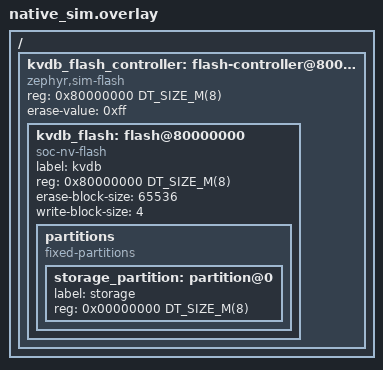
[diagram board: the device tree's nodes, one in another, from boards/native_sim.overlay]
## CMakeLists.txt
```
#-------------------------------------------------------------------------------
# kvdb diagnostics: a shell over the storage stack
#
# Copyright (c) 2026
# SPDX-License-Identifier: Apache-2.0

cmake_minimum_required(VERSION 3.20.0)
find_package(Zephyr REQUIRED HINTS $ENV{ZEPHYR_BASE})

project(app_diag LANGUAGES C)

target_sources(app PRIVATE src/main.c)

# `diag`: structure recognition, with the formats compiled in here.
target_sources_ifdef(CONFIG_APP_DIAG_STRUCT app PRIVATE
	src/diag_shell.c
	src/diag_decode.c
	src/diag_cbor.c
)
```

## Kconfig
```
# kvdb diagnostics app — Kconfig entry point.
#
# Copyright (c) 2026
# SPDX-License-Identifier: Apache-2.0

menu "Zephyr"
source "Kconfig.zephyr"
endmenu

module = APP_DIAG
module-str = APP_DIAG
source "subsys/logging/Kconfig.template.log_config"

config APP_DIAG_MOUNT_AT_BOOT
	bool "Mount blob_db at boot"
	help
	  Call blob_db_mount() from main() before the shell takes over, as
	  `blob_db mount` would.

	  Off by default because mounting is not read-only. A mount finishes
	  an interrupted compaction from the scratch seal, formats a partition
	  whose master sectors both read as erased, and, on the UBI backend,
	  attaches the volume. Each of those writes flash, and each can change
	  the state a diagnostic session was meant to look at. Off, the app
	  touches the storage partition only through the commands typed at it:
	  "flash" reads raw bytes, "blob_db" answers "not mounted" until
	  `blob_db mount` or `blob_db format yes` is run.

config APP_DIAG_STRUCT
	bool "diag: recognise and decode structures"
	default y
	depends on SHELL && BLOB_DB_INSPECT
	help
	  Add a `diag` shell group that names what each live object is: the
	  root registry, kvdb and blobfs metas, the persondb superblock,
	  kvhash directories and buckets, logring roots and entries. `scan`
	  classifies every object and counts them by type, `roots` walks the
	  root registry one level down, `show` decodes one object.

	  The formats, the current ones and those earlier builds wrote, are
	  compiled into app_diag (src/diag_decode.c); the libraries carry none
	  of this. Read-only: only blob_db_size(), blob_db_read() and the
	  inspect API are called.

config APP_DIAG_BUF_SIZE
	int "Bytes of one object diag reads"
	default BLOB_DB_MAX_PAYLOAD_LEN
	range 64 65536
	depends on APP_DIAG_STRUCT
	help
	  An object is read into one static buffer of this size to be
	  classified and decoded. A larger object is judged by its first
	  bytes only. Every structure head and kvhash bucket fits in one
	  payload, so the default covers all of them.

config APP_DIAG_HINTS_MAX
	int "References diag tracks from the root registry"
	default 32
	range 4 1024
	depends on APP_DIAG_STRUCT
	help
	  `diag scan` labels the registry's roots, and what each root points
	  at, with where they are referenced from, and lists those that name
	  no object. This many fit; 24 bytes each.
```

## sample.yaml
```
sample:
  description: kvdb diagnostics shell (existing commands, no mount by default)
  name: kvdb-diag
common:
  tags: [storage, shell]
  harness: console
tests:
  # The default build: boots to the shell and leaves the store unmounted.
  app.diag:
    platform_allow:
      - native_sim
    integration_platforms:
      - native_sim
    harness_config:
      type: multi_line
      ordered: true
      regex:
        - "kvdb diag: UBI backend, storage partition 8192 KiB"
        - "kvdb diag: not mounted"

  # Mount at boot opted in: a blank image is formatted and mounted.
  app.diag.mount:
    platform_allow:
      - native_sim
    extra_configs:
      - CONFIG_APP_DIAG_MOUNT_AT_BOOT=y
    harness_config:
      type: one_line
      regex:
        - "kvdb diag: mounted"

  # The lifecycle commands, typed at the shell: format refused without `yes`,
  # mount, remount, unmount, format. Commands and replies: test_shell.yml.
  app.diag.admin:
    platform_allow:
      - native_sim
    harness: shell
    harness_config:
      shell_commands_file: test_shell.yml

  # `kernel reboot cold` restarts unmounted, and the store formatted before it
  # mounts again without being formatted. A pytest test rather than a
  # test_shell.yml step: the restarted shell's first prompt needs waiting for.
  app.diag.reboot:
    platform_allow:
      - native_sim
    harness: pytest
    harness_config:
      pytest_root:
        - "pytest/test_reboot.py"

  # A dump made on the host is imported line by line into a fresh store and
  # exported again: every object comes back at its own id, with next_id.
  app.diag.export:
    platform_allow:
      - native_sim
    harness: pytest
    harness_config:
      pytest_root:
        - "pytest/test_export.py"

  # The same with large payloads: one object is segmented.
  app.diag.export.large:
    platform_allow:
      - native_sim
    extra_configs:
      - CONFIG_BLOB_DB_LARGE_PAYLOADS=y
    harness: pytest
    harness_config:
      pytest_root:
        - "pytest/test_export.py"

  # `diag`: a store imported from pytest/diag_fixtures.py, one object in every
  # structure format diag knows, current and past, is scanned, walked from
  # the registry and decoded object by object. One device for the module:
  # the store is imported once.
  app.diag.structs:
    platform_allow:
      - native_sim
    harness: pytest
    harness_config:
      pytest_dut_scope: module
      pytest_root:
        - "pytest/test_structs.py"
```

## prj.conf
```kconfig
# kvdb diagnostics app: the storage stack plus the shell commands that already
# exist for it. The app adds no commands of its own.
#
# Copyright (c) 2026
# SPDX-License-Identifier: Apache-2.0

# A diagnostics build compiles in the stack's debug messages, which a product
# build leaves out: mount's master classification, recovery decisions, UBI
# attach. They are on from boot; `log enable <level> <module>` turns a module
# down at run time.
#
# Immediate mode: each message is printed by the call that logs it, so it
# lands before the shell's reply to the command that caused it, and a burst of
# debug output is not dropped from a full buffer.
CONFIG_LOG=y
CONFIG_LOG_MODE_IMMEDIATE=y
CONFIG_LOG_RUNTIME_FILTERING=y
CONFIG_LOG_RUNTIME_DEFAULT_LEVEL=4
CONFIG_APP_DIAG_LOG_LEVEL_DBG=y
CONFIG_BLOB_DB_LOG_LEVEL_DBG=y
CONFIG_UBI_LOG_LEVEL_DBG=y

# The store, on the default backend (UBI with the built-in key). An image is
# readable only by a build that agrees with the one that wrote it on the
# backend, the UBI key and every option that changes the on-flash format
# (BLOB_DB_LARGE_PAYLOADS, BLOB_DB_MAX_PAYLOAD_LEN); match those to the
# firmware whose store is being inspected.
CONFIG_BLOB_DB=y

# Nothing in the build may write the partition on its own. The store is
# mounted by `blob_db mount`, or at boot only with
# CONFIG_APP_DIAG_MOUNT_AT_BOOT (default n); a corrupt one
# is never reformatted; no work item runs maintenance in the background; and
# blobfs is left out, since its file-system registration is another way to a
# mount.
CONFIG_BLOB_DB_AUTOFORMAT_ON_CORRUPT=n
CONFIG_BLOB_DB_MAINT_WORK=n

# The existing command groups.
CONFIG_SHELL=y
CONFIG_SHELL_PROMPT_UART="kvdb:~$ "
# blob_db info|stats|buckets|bucket|id|dump|maintain
CONFIG_BLOB_DB_SHELL=y
# blob_db iostats
CONFIG_BLOB_DB_IOSTATS=y
# blob_db mount|unmount|format yes
CONFIG_BLOB_DB_SHELL_ADMIN=y
# flash read|write|erase|... on the raw device
CONFIG_FLASH_SHELL=y
# kernel threads|stacks|uptime, device list
CONFIG_KERNEL_SHELL=y
CONFIG_DEVICE_SHELL=y
# kernel reboot cold|warm. Not an unmount: the store sees what it would see
# after a power cut between operations. On native_sim the process re-runs
# itself with the same arguments, so --kvdb=<file> and its content carry over.
CONFIG_REBOOT=y

# Export reads each object 32 bytes at a time, and without an index every
# blob_db_read() walks the object's whole bucket, one 12-byte read per slot:
# on a 13k-object store that is ~800 MB read to export 4.6 MB. With the slot
# index the first lookup of an object walks once and the rest go straight to
# its slot. It is a cache of hints (CLOCK keeps the ids in use; only the
# object being exported needs to stay), every hit is checked against flash,
# and nothing about it is written: it changes no answer and no byte on the
# store. Walks and known-offset reads fetch 512 bytes at a time instead of
# one slot header or one field per flash command. RAM: 3 KB of index plus
# 1.5 KB of bucket cursors.
CONFIG_BLOB_DB_SLOT_INDEX=y
CONFIG_BLOB_DB_SLOT_INDEX_CLOCK=y
CONFIG_BLOB_DB_SLOT_INDEX_ENTRIES=256
CONFIG_BLOB_DB_WALK_CHUNK=512
CONFIG_BLOB_DB_READ_WINDOW=512

# `blob_db maintain` with a budget runs UBI relocations, and their AES-CMAC,
# on the shell thread.
CONFIG_SHELL_STACK_SIZE=16384

# A mount at boot runs on main: UBI attach plus blob_db's master and bucket
# scan, the same work app_perf_blob_db gives 32 KB.
CONFIG_MAIN_STACK_SIZE=32768
```

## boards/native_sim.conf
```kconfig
# The shell on the terminal native_sim was started from, not on a pty, so the
# host build is used like any command-line tool; commands can also be piped in.
CONFIG_UART_NATIVE_PTY_0_ON_STDINOUT=y

# Program-over-programmed (1->0 only) is legal on the NOR this geometry
# models; the flash simulator refuses it unless told otherwise.
CONFIG_FLASH_SIMULATOR_DOUBLE_WRITES=y

# The overlay gives the store's flash the DK's 64 KB erase blocks; blob_db
# refuses to mount a sector larger than its sector buffer.
CONFIG_BLOB_DB_SECTOR_BUF_SIZE=65536

# zephyr-ubi's heap: 8 B per erase block (128 of 64 KB, so 1 KB) plus a
# handle and scratch buffer at attach and a second pair during a format.
CONFIG_BLOB_DB_UBI_HEAP_SIZE=6144

# The native log backend already prints to the terminal the shell is on; the
# shell's own log backend would print every line a second time.
CONFIG_SHELL_LOG_BACKEND=n

# `kernel reboot` re-runs the executable with the same arguments, so the
# image named by --kvdb survives it. Without this it only exits.
CONFIG_NATIVE_SIM_REBOOT=y

# `blob_db import` stages each object whole, so the host build restores any
# object up to BLOB_DB_MAX_OBJECT_LEN's default with one blob_db_update(), as
# the original was written.
CONFIG_BLOB_DB_SHELL_IMPORT_BUF_SIZE=131072

# The shell polls its input every 10 ms by default; a host feeding
# `blob_db import` one line at a time waits that long per line.
CONFIG_SHELL_BACKEND_SERIAL_RX_POLL_PERIOD=1
```

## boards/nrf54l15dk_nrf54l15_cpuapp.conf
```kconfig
# blob_db stages a whole erase block in .bss; the MX25R6435F's is 64 KB.
CONFIG_BLOB_DB_SECTOR_BUF_SIZE=65536

# zephyr-ubi's heap: 8 B per erase block (128 of 64 KB, so 1 KB) plus a handle
# and scratch buffer at attach and a second pair during a format.
CONFIG_BLOB_DB_UBI_HEAP_SIZE=6144

# RAM: the nRF54L15 has 256 KB. AES T-tables (zephyr-ubi's header CMAC) in
# flash instead of RAM: 8 KB.
CONFIG_MBEDTLS_AES_ROM_TABLES=y
```

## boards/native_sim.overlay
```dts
/*
 * Copyright (c) 2026
 * SPDX-License-Identifier: Apache-2.0
 *
 * native_sim: the store gets a simulated flash device of its own, shaped like
 * the nRF5340-DK's on-board MX25R6435F partition (8 MB, 64 KB erase blocks,
 * 4 B write alignment, erased = 0xff). The partition starts at offset 0 and
 * fills the device, so the device's backing file IS a partition image:
 *
 *   ./zephyr.exe --kvdb=storage.bin
 *
 * opens a raw dump of the DK's storage partition as it is, and a file the
 * host build leaves behind can be programmed back unchanged.
 *
 * The board's own flash0 keeps its MCUboot and image partitions; only its
 * small storage partition is removed so that storage_partition, the node
 * label blob_db binds to, names this one.
 */

/delete-node/ &storage_partition;

/ {
	kvdb_flash_controller: flash-controller@80000000 {
		compatible = "zephyr,sim-flash";
		reg = <0x80000000 DT_SIZE_M(8)>;
		ranges;
		#address-cells = <1>;
		#size-cells = <1>;
		erase-value = <0xff>;

		kvdb_flash: flash@80000000 {
			compatible = "soc-nv-flash";
			/* Names the --kvdb, --kvdb_erase, --kvdb_rm and --kvdb_in_ram
			 * command-line options of the flash simulator.
			 */
			label = "kvdb";
			reg = <0x80000000 DT_SIZE_M(8)>;
			erase-block-size = <65536>;
			write-block-size = <4>;

			partitions {
				compatible = "fixed-partitions";
				#address-cells = <1>;
				#size-cells = <1>;

				storage_partition: partition@0 {
					label = "storage";
					reg = <0x00000000 DT_SIZE_M(8)>;
				};
			};
		};
	};
};
```

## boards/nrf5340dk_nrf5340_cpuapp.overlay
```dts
/*
 * The store on the on-board MX25R64 QSPI NOR: its first 8 MB, 64 KB sectors,
 * as in app_perf_blob_db. The native_sim build of this app models the same
 * partition, so a raw dump of this range opens there unchanged.
 */

/delete-node/ &storage_partition;

&mx25r64 {
	partitions {
		compatible = "fixed-partitions";
		#address-cells = <1>;
		#size-cells = <1>;

		storage_partition: partition@0 {
			label = "storage";
			reg = <0x00000000 0x00800000>;
		};
	};
};
```

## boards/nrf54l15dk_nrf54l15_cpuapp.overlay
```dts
/*
 * The store on the nRF54L15-DK's MX25R64: the same chip as the nRF5340-DK's,
 * but on SPI00 (jedec,spi-nor, single line, 8 MHz) rather than QSPI. The whole
 * chip, 64 KB sectors, as app_cbor_persondb and nrf_ble_scanner_with_db lay it
 * out on this board.
 *
 * The SoC's internal storage_partition (RRAM) is removed so that the label
 * "storage" names the external part only.
 *
 * spi-nor's write block is 1 B (QSPI: 4 B), so an image written here does not
 * open on the nRF5340-DK build or on native_sim's default, and the other way
 * round.
 */

/delete-node/ &storage_partition;

&mx25r64 {
	partitions {
		compatible = "fixed-partitions";
		#address-cells = <1>;
		#size-cells = <1>;

		storage_partition: partition@0 {
			label = "storage";
			reg = <0x00000000 0x00800000>;
		};
	};
};
```

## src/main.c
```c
/*
 * Copyright (c) 2026
 * SPDX-License-Identifier: Apache-2.0
 *
 * kvdb diagnostics: an application that does nothing but expose the shell.
 *
 * The commands are the ones the libraries and Zephyr register (blob_db,
 * flash, kernel, device), plus the app's own `diag` (diag_shell.c), which
 * recognises the structures in the store. This file says what was built, and
 * mounts the store only when CONFIG_APP_DIAG_MOUNT_AT_BOOT asks for it: by
 * default nothing writes the storage partition until a command typed at the
 * shell does (`blob_db mount`, `blob_db format yes`, `flash write`).
 */

#include <zephyr/kernel.h>
#include <zephyr/logging/log.h>
#include <zephyr/storage/flash_map.h>

#include <app/lib/blob_db.h>

LOG_MODULE_REGISTER(app_diag, CONFIG_APP_DIAG_LOG_LEVEL);

int main(void)
{
	LOG_INF("kvdb diag: %s backend, storage partition %u KiB on %s",
		IS_ENABLED(CONFIG_BLOB_DB_BACKEND_UBI) ? "UBI" : "flash_area",
		(unsigned int)(PARTITION_SIZE(storage_partition) / 1024U),
		PARTITION_DEVICE(storage_partition)->name);

	if (!IS_ENABLED(CONFIG_APP_DIAG_MOUNT_AT_BOOT)) {
		LOG_INF("kvdb diag: not mounted; `blob_db mount` mounts");
		return 0;
	}

	int rc = blob_db_mount();

	if (rc != 0) {
		LOG_ERR("kvdb diag: mount failed: %d", rc);
		return 0;
	}
	LOG_INF("kvdb diag: mounted");
	return 0;
}
```

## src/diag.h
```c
/*
 * Copyright (c) 2026
 * SPDX-License-Identifier: Apache-2.0
 *
 * app_diag structure recognition: what a blob is, judged from its bytes.
 *
 * The formats are the ones the libraries write, copied here on purpose
 * together with the layouts earlier builds wrote, so that an image from an
 * older firmware is still named and decoded. Nothing in this directory is
 * used by the libraries, and nothing here calls into a container: the only
 * dependency is the public blob_db API (plus the inspect API to enumerate).
 *
 * Every judgement is a guess from the bytes. A magic and a length that agree
 * with it make a strong guess; a layout without a magic (a kvhash bucket, a
 * logring entry) is a weak one, reported as "shape". A file body or a spilled
 * value can hold any bytes, including another structure's magic.
 */

#ifndef APP_DIAG_DIAG_H_
#define APP_DIAG_DIAG_H_

#include <stdbool.h>
#include <stddef.h>
#include <stdint.h>

struct shell;

/** What a blob was recognised as. The order is the order of the summary. */
enum diag_type {
	DIAG_T_RREG,          /**< root registry (id 1)                       */
	DIAG_T_KVDB_META,     /**< kvdb instance meta                         */
	DIAG_T_BLOBFS_META,   /**< blobfs file-system meta                    */
	DIAG_T_PADB_SB,       /**< app_cbor_persondb superblock (CBOR)        */
	DIAG_T_KVHASH_DIR,    /**< kvhash directory (map root or sub-map)     */
	DIAG_T_CLOG_ROOT,     /**< logring: root i-node or whole ring         */
	DIAG_T_KVHASH_BUCKET, /**< kvhash bucket (shape only)                 */
	DIAG_T_CLOG_ENTRY,    /**< logring chain entry (shape only)           */
	DIAG_T_CBOR,          /**< one well-formed CBOR item (shape only)     */
	DIAG_T_EMPTY,         /**< zero-length payload                        */
	DIAG_T_UNKNOWN,       /**< none of the above                          */
	DIAG_T_COUNT,
};

/** Most variants any one type has; see diag_type_info(). */
#define DIAG_VARIANTS_MAX 4

/** The verdict on one blob. */
struct diag_class {
	enum diag_type type;
	uint8_t variant;    /**< index into the type's variant names     */
	bool    shape;      /**< no magic: recognised by layout alone    */
	bool    suspect;    /**< magic matches, the rest does not quite  */
	const char *note;   /**< static text: why suspect, or a state    */
};

/** Static description of a type, for summaries and `diag formats`. */
struct diag_type_info {
	const char *name;                             /**< short tag    */
	const char *what;                             /**< one line     */
	const char *variant[DIAG_VARIANTS_MAX];       /**< NULL-ended   */
};

const struct diag_type_info *diag_type_info(enum diag_type t);

/** Look a type up by its short tag (for `diag show <id> <type>`). */
int diag_type_by_name(const char *name, enum diag_type *out);

/**
 * @brief Classify a blob.
 *
 * @param id    the blob's id (a logring entry links forward, to a larger id)
 * @param buf   the payload, or its first @p n bytes
 * @param n     bytes in @p buf
 * @param size  the blob's full length; > @p n when only a prefix was read,
 *              in which case the shape-only checks, which need the whole
 *              payload, are skipped
 */
void diag_classify(uint64_t id, const uint8_t *buf, size_t n, size_t size,
		   struct diag_class *out);

/**
 * @brief Classify a blob as type @p t whatever its bytes say, for decoding
 *        a blob without a magic (a kvhash bucket, a logring entry) or one
 *        the classifier got wrong.
 *
 * @retval 0         @p out filled; marked suspect if @p t is not what
 *                   diag_classify() would have said
 * @retval -EMSGSIZE too short to hold a @p t header
 */
int diag_force(uint64_t id, enum diag_type t, const uint8_t *buf, size_t n,
	       size_t size, struct diag_class *out);

/**
 * @brief One line: the id, type, variant and the fields that identify the
 *        instance, after @p prefix (indentation, a label) and before
 *        @p suffix (who references it); either may be "".
 */
void diag_summary(const struct shell *sh, const char *prefix, uint64_t id,
		  const struct diag_class *c, const uint8_t *buf, size_t n,
		  size_t size, const char *suffix);

/**
 * @brief Decode a blob in full, as type @p c->type, variant @p c->variant.
 *
 * Every id the structure references is printed, so that the next
 * `diag show` can follow it.
 */
void diag_decode(const struct shell *sh, uint64_t id,
		 const struct diag_class *c, const uint8_t *buf, size_t n,
		 size_t size);

/** One id a structure's head points at. */
struct diag_ref {
	uint64_t id;
	const char *label;  /**< static: what the field is ("struct_root") */
};

/**
 * @brief The ids a structure head references, as far as one blob tells:
 *        a kvdb meta's map, a blobfs meta's root directory, a persondb
 *        superblock's tables, a logring root's head. A kvhash directory's
 *        children are not listed here (they can be hundreds); `diag show`
 *        prints them.
 *
 * @return number of refs written to @p out (at most @p max)
 */
int diag_refs(const struct diag_class *c, const uint8_t *buf, size_t n,
	      struct diag_ref *out, int max);

/* ---- root registry keys --------------------------------------------- */

/** Name of a registry key's FourCC when it is one this tool knows, or NULL. */
const char *diag_rreg_key_name(uint64_t key);

/**
 * @brief Walk a root registry image.
 * @retval 0       walked
 * @retval -EINVAL not a registry this tool reads
 */
int diag_rreg_foreach(const uint8_t *buf, size_t n,
		      void (*cb)(uint64_t key, uint64_t root, void *user),
		      void *user);

/* ---- CBOR (diag_cbor.c) ---------------------------------------------- */

/** Length of the one well-formed item at @p p, or a negative errno. */
int diag_cbor_item_len(const uint8_t *p, size_t n, size_t *len);

/**
 * @brief Format the item at @p p in CBOR diagnostic notation, compactly
 *        (`{1: 2, 2: [5, 6], 3: "ab"}`), into @p out. Long output ends in
 *        "...".
 * @return bytes of input consumed, or a negative errno
 */
int diag_cbor_format(const uint8_t *p, size_t n, char *out, size_t out_sz);

/** Minimal reader for decoding known CBOR layouts field by field. */
struct diag_cbor {
	const uint8_t *p;
	const uint8_t *end;
	bool err;
};

/** Major type of the next item (0..7), or -1 at the end or on error. */
int diag_cbor_peek(const struct diag_cbor *c);
/** Unsigned integer (major 0). */
bool diag_cbor_uint(struct diag_cbor *c, uint64_t *v);
/** Definite-length array (major 4) or map (major 5) header. */
bool diag_cbor_array(struct diag_cbor *c, uint64_t *n);
bool diag_cbor_map(struct diag_cbor *c, uint64_t *n);
/** Skip one whole item. */
bool diag_cbor_skip(struct diag_cbor *c);

#endif /* APP_DIAG_DIAG_H_ */
```

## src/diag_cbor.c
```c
/*
 * Copyright (c) 2026
 * SPDX-License-Identifier: Apache-2.0
 *
 * A small CBOR (RFC 8949) reader for app_diag: check that bytes are one
 * well-formed item, print it in diagnostic notation, and pick known layouts
 * apart field by field. It knows nothing of any schema, so it prints a record
 * a newer firmware wrote as faithfully as one this build could write.
 *
 * zcbor is not used: the decoders it generates take one schema each, and the
 * point here is to show bytes whose schema may not be the one compiled in.
 */

#include <errno.h>
#include <stdarg.h>
#include <string.h>

#include <zephyr/sys/printk.h>
#include <zephyr/sys/util.h>

#include "diag.h"

#define CBOR_DEPTH_MAX 16
#define CBOR_BREAK     0xff
#define CBOR_AI_INDEF  31

/* Read an item head: major type, argument, and whether the length is
 * indefinite. Advances *pp. */
static int head(const uint8_t **pp, const uint8_t *end, uint8_t *major,
		uint64_t *arg, bool *indef)
{
	const uint8_t *p = *pp;

	if (p >= end) {
		return -ENODATA;
	}
	const uint8_t ib = *p++;
	const uint8_t ai = ib & 0x1f;

	*major = ib >> 5;
	*indef = false;
	if (ai < 24) {
		*arg = ai;
	} else if (ai <= 27) {
		const size_t w = 1u << (ai - 24);

		if ((size_t)(end - p) < w) {
			return -ENODATA;
		}
		*arg = 0;
		for (size_t i = 0; i < w; i++) {
			*arg = (*arg << 8) | *p++;
		}
	} else if (ai == CBOR_AI_INDEF &&
		   (*major == 2 || *major == 3 || *major == 4 || *major == 5)) {
		*indef = true;
		*arg = 0;
	} else {
		return -EILSEQ;   /* reserved, or a stray break */
	}
	*pp = p;
	return 0;
}

static int skip(const uint8_t **pp, const uint8_t *end, int depth)
{
	uint8_t major;
	uint64_t arg;
	bool indef;

	if (depth > CBOR_DEPTH_MAX) {
		return -ELOOP;
	}
	int rc = head(pp, end, &major, &arg, &indef);

	if (rc < 0) {
		return rc;
	}
	switch (major) {
	case 0: case 1: case 7:
		return 0;
	case 2: case 3:
		if (indef) {
			/* Chunks of the same major type, then a break. */
			while (*pp < end && **pp != CBOR_BREAK) {
				if ((**pp >> 5) != major) {
					return -EILSEQ;
				}
				rc = skip(pp, end, depth + 1);
				if (rc < 0) {
					return rc;
				}
			}
			if (*pp >= end) {
				return -ENODATA;
			}
			(*pp)++;
			return 0;
		}
		if (arg > (uint64_t)(end - *pp)) {
			return -ENODATA;
		}
		*pp += arg;
		return 0;
	case 6:
		return skip(pp, end, depth + 1);
	default: { /* 4: array, 5: map */
		const uint64_t per = (major == 5) ? 2 : 1;

		if (indef) {
			uint64_t items = 0;

			while (*pp < end && **pp != CBOR_BREAK) {
				rc = skip(pp, end, depth + 1);
				if (rc < 0) {
					return rc;
				}
				items++;
			}
			if (*pp >= end || items % per) {
				return *pp >= end ? -ENODATA : -EILSEQ;
			}
			(*pp)++;
			return 0;
		}
		/* Every item takes at least one byte: a count past the end
		 * is malformed, and bounding it here bounds the loop. */
		if (arg > (uint64_t)(end - *pp)) {
			return -ENODATA;
		}
		for (uint64_t i = 0; i < arg * per; i++) {
			rc = skip(pp, end, depth + 1);
			if (rc < 0) {
				return rc;
			}
		}
		return 0;
	}
	}
}

int diag_cbor_item_len(const uint8_t *p, size_t n, size_t *len)
{
	const uint8_t *q = p;
	int rc = skip(&q, p + n, 0);

	if (rc < 0) {
		return rc;
	}
	*len = (size_t)(q - p);
	return 0;
}

/* ---- diagnostic notation --------------------------------------------- */

struct fmt {
	char *buf;
	size_t sz;
	size_t len;
	bool full;
};

static __printf_like(2, 3) void put(struct fmt *f, const char *s, ...)
{
	if (f->full) {
		return;
	}
	va_list ap;

	va_start(ap, s);
	const int n = vsnprintk(f->buf + f->len, f->sz - f->len, s, ap);

	va_end(ap);
	/* Four bytes are always kept free for the "..." that marks a
	 * truncated line. */
	if (n < 0 || f->len + (size_t)n + 4 > f->sz) {
		f->full = true;
		strcpy(f->buf + f->sz - 4, "...");
		f->len = f->sz - 1;
		return;
	}
	f->len += (size_t)n;
}

#define FMT_BYTES_MAX 16

static int format(const uint8_t **pp, const uint8_t *end, struct fmt *f,
		  int depth)
{
	uint8_t major;
	uint64_t arg;
	bool indef;

	if (depth > CBOR_DEPTH_MAX) {
		return -ELOOP;
	}
	const uint8_t ib = (*pp < end) ? **pp : 0;
	int rc = head(pp, end, &major, &arg, &indef);

	if (rc < 0) {
		return rc;
	}
	switch (major) {
	case 0:
		put(f, "%llu", (unsigned long long)arg);
		return 0;
	case 1:
		if (arg == UINT64_MAX) {
			put(f, "-18446744073709551616");
		} else {
			put(f, "-%llu", (unsigned long long)arg + 1);
		}
		return 0;
	case 2: case 3:
		if (indef) {
			/* Shown as the chunks it was sent in, RFC 8949 §8. */
			put(f, "(_ ");
			for (int i = 0; *pp < end && **pp != CBOR_BREAK; i++) {
				put(f, i ? ", " : "");
				rc = format(pp, end, f, depth + 1);
				if (rc < 0) {
					return rc;
				}
			}
			if (*pp >= end) {
				return -ENODATA;
			}
			(*pp)++;
			put(f, ")");
			return 0;
		}
		if (arg > (uint64_t)(end - *pp)) {
			return -ENODATA;
		}
		if (major == 2) {
			put(f, "h'");
			for (uint64_t i = 0; i < MIN(arg, FMT_BYTES_MAX); i++) {
				put(f, "%02x", (*pp)[i]);
			}
			put(f, arg > FMT_BYTES_MAX ? "..'" : "'");
		} else {
			put(f, "\"");
			for (uint64_t i = 0; i < arg; i++) {
				const char c = (char)(*pp)[i];

				put(f, "%c", (c >= 0x20 && c < 0x7f && c != '"') ?
				    c : '.');
			}
			put(f, "\"");
		}
		*pp += arg;
		return 0;
	case 6:
		put(f, "%llu(", (unsigned long long)arg);
		rc = format(pp, end, f, depth + 1);
		put(f, ")");
		return rc;
	case 7:
		switch (arg) {
		case 20: put(f, "false"); break;
		case 21: put(f, "true"); break;
		case 22: put(f, "null"); break;
		case 23: put(f, "undefined"); break;
		default:
			/* Floats are shown by their bits: printk has no %f. */
			if (ib >= 0xf9 && ib <= 0xfb) {
				put(f, "float(0x%llx)", (unsigned long long)arg);
			} else {
				put(f, "simple(%llu)", (unsigned long long)arg);
			}
			break;
		}
		return 0;
	default: { /* 4: array, 5: map */
		const bool map = (major == 5);

		put(f, map ? "{" : "[");
		put(f, indef ? "_ " : "");
		if (!indef && arg > (uint64_t)(end - *pp)) {
			return -ENODATA;
		}
		for (uint64_t i = 0;; i++) {
			if (indef) {
				if (*pp >= end) {
					return -ENODATA;
				}
				if (**pp == CBOR_BREAK) {
					(*pp)++;
					break;
				}
			} else if (i == arg) {
				break;
			}
			put(f, i ? ", " : "");
			rc = format(pp, end, f, depth + 1);
			if (rc < 0) {
				return rc;
			}
			if (map) {
				put(f, ": ");
				rc = format(pp, end, f, depth + 1);
				if (rc < 0) {
					return rc;
				}
			}
		}
		put(f, map ? "}" : "]");
		return 0;
	}
	}
}

int diag_cbor_format(const uint8_t *p, size_t n, char *out, size_t out_sz)
{
	struct fmt f = { .buf = out, .sz = out_sz };
	const uint8_t *q = p;

	if (out_sz < 8) {
		return -ENOMEM;
	}
	out[0] = '\0';
	int rc = format(&q, p + n, &f, 0);

	return rc < 0 ? rc : (int)(q - p);
}

/* ---- field reader ---------------------------------------------------- */

int diag_cbor_peek(const struct diag_cbor *c)
{
	return (c->err || c->p >= c->end) ? -1 : (*c->p >> 5);
}

static bool expect(struct diag_cbor *c, uint8_t want, uint64_t *v)
{
	uint8_t major;
	bool indef;

	if (c->err || head(&c->p, c->end, &major, v, &indef) < 0 ||
	    major != want || indef) {
		c->err = true;
		return false;
	}
	return true;
}

bool diag_cbor_uint(struct diag_cbor *c, uint64_t *v)
{
	return expect(c, 0, v);
}

bool diag_cbor_array(struct diag_cbor *c, uint64_t *n)
{
	return expect(c, 4, n);
}

bool diag_cbor_map(struct diag_cbor *c, uint64_t *n)
{
	return expect(c, 5, n);
}

bool diag_cbor_skip(struct diag_cbor *c)
{
	if (c->err || skip(&c->p, c->end, 0) < 0) {
		c->err = true;
		return false;
	}
	return true;
}
```

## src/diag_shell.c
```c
/*
 * Copyright (c) 2026
 * SPDX-License-Identifier: Apache-2.0
 *
 * `diag`: name and decode the structures in a mounted store.
 *
 *   diag scan [-a]          every live object, classified; a census by type
 *   diag roots              the root registry, each root, what it points at
 *   diag show <id> [type]   one object decoded in full
 *   diag formats            the formats and past variants this build knows
 *
 * Read-only: only blob_db_size(), blob_db_read() and the inspect API are
 * called. The formats are in diag_decode.c; nothing here calls a container.
 */

#include <errno.h>
#include <stdlib.h>
#include <string.h>

#include <zephyr/shell/shell.h>
#include <zephyr/sys/printk.h>
#include <zephyr/sys/util.h>

#include <app/lib/blob_db.h>
#include <app/lib/blob_db_inspect.h>

#include "diag.h"

/* Ids gathered from a bucket per pass of its sector, as export does. */
#define SCAN_IDS  32
/* References followed per root by `roots` and the scan's labels. */
#define REFS_MAX  8

/* One object at a time: the shell thread is the only user. */
static uint8_t __aligned(4) g_buf[CONFIG_APP_DIAG_BUF_SIZE];

/* What points at an id, from the registry down one level: the labels the
 * scan prints, and the roots it checks are bound. */
struct hint {
	uint64_t id;
	uint64_t key;       /* registry key, for a root                    */
	uint64_t parent;    /* the root it hangs off; 0 for a root          */
	const char *label;  /* field in the parent                          */
	bool seen;
};

static struct hint g_hint[CONFIG_APP_DIAG_HINTS_MAX];
static int g_n_hint;
static bool g_hint_full;

static int parse_u64(const struct shell *sh, const char *s, uint64_t *out)
{
	char *end;

	errno = 0;
	*out = strtoull(s, &end, 0);
	if (errno || end == s || *end != '\0') {
		shell_error(sh, "not a number: %s", s);
		return -EINVAL;
	}
	return 0;
}

static int need_mount(const struct shell *sh, struct blob_db_inspect_info *in)
{
	int rc = blob_db_inspect_info_get(in);

	if (rc == -ENODEV) {
		shell_error(sh, "blob_db not mounted");
	} else if (rc < 0) {
		shell_error(sh, "info: %d", rc);
	}
	return rc;
}

/* Read an object, or its first sizeof(g_buf) bytes, into g_buf. */
static int read_obj(uint64_t id, size_t *size, size_t *n)
{
	int rc = blob_db_size(id, size);

	if (rc < 0) {
		return rc;
	}
	const size_t want = MIN(*size, sizeof(g_buf));
	size_t off = 0;

	while (off < want) {
		size_t got;

		rc = blob_db_read(id, off, g_buf + off, want - off, &got);
		if (rc < 0) {
			return rc;
		}
		if (got == 0) {
			return -EIO;   /* shrank since its size was taken */
		}
		off += got;
	}
	*n = want;
	return 0;
}

/* ---- hints ----------------------------------------------------------- */

static void hint_add(uint64_t id, uint64_t key, uint64_t parent,
		     const char *label)
{
	if (g_n_hint == ARRAY_SIZE(g_hint)) {
		g_hint_full = true;
		return;
	}
	g_hint[g_n_hint++] = (struct hint){
		.id = id, .key = key, .parent = parent, .label = label,
	};
}

static void hint_root(uint64_t key, uint64_t root, void *user)
{
	ARG_UNUSED(user);
	hint_add(root, key, 0, NULL);
}

/* The registry's roots, then what each root points at. Leaves g_buf
 * holding the last root read. */
static void hints_load(void)
{
	size_t size, n;

	g_n_hint = 0;
	g_hint_full = false;
	if (read_obj(BLOB_DB_ROOT_ID, &size, &n) < 0 ||
	    diag_rreg_foreach(g_buf, n, hint_root, NULL) < 0) {
		return;
	}
	const int n_roots = g_n_hint;

	for (int i = 0; i < n_roots; i++) {
		struct diag_class c;
		struct diag_ref refs[REFS_MAX];

		if (read_obj(g_hint[i].id, &size, &n) < 0) {
			continue;
		}
		diag_classify(g_hint[i].id, g_buf, n, size, &c);
		const int k = diag_refs(&c, g_buf, n, refs, ARRAY_SIZE(refs));

		for (int j = 0; j < k; j++) {
			hint_add(refs[j].id, g_hint[i].key, g_hint[i].id,
				 refs[j].label);
		}
	}
}

static struct hint *hint_find(uint64_t id)
{
	for (int i = 0; i < g_n_hint; i++) {
		if (g_hint[i].id == id) {
			return &g_hint[i];
		}
	}
	return NULL;
}

static void key_text(uint64_t key, char *out, size_t sz)
{
	const char *name = diag_rreg_key_name(key);
	char cc[5];

	for (int i = 0; i < 4; i++) {
		const char ch = (char)(key >> (56 - 8 * i));

		cc[i] = (ch >= 0x20 && ch < 0x7f) ? ch : '.';
	}
	cc[4] = '\0';
	snprintk(out, sz, "'%s'/0x%08x%s%s", cc, (uint32_t)key,
		 name ? " " : "", name ? name : "");
}

static void hint_text(const struct hint *h, char *out, size_t sz)
{
	char key[40];

	if (!h) {
		out[0] = '\0';
		return;
	}
	key_text(h->key, key, sizeof(key));
	if (h->parent) {
		snprintk(out, sz, "  <- %llu.%s", (unsigned long long)h->parent,
			 h->label);
	} else {
		snprintk(out, sz, "  <- rootreg %s", key);
	}
}

/* ---- diag scan ------------------------------------------------------- */

struct scan {
	const struct shell *sh;
	bool all;
	uint32_t count[DIAG_T_COUNT][DIAG_VARIANTS_MAX];
	uint64_t bytes[DIAG_T_COUNT][DIAG_VARIANTS_MAX];
	uint32_t objects, suspects, errors, printed;
	uint64_t total;
};

struct id_batch {
	uint64_t ids[SCAN_IDS];
	uint32_t skip;
	uint16_t n;
	bool more;
};

static int collect_live(const struct blob_db_inspect_slot *s, void *user)
{
	struct id_batch *b = user;

	if (s->state != BLOB_DB_INSPECT_LIVE || s->segment) {
		return 0;
	}
	if (b->skip) {
		b->skip--;
		return 0;
	}
	if (b->n == SCAN_IDS) {
		b->more = true;
		return 1;
	}
	b->ids[b->n++] = s->id;
	return 0;
}

static void scan_one(struct scan *s, uint64_t id)
{
	struct diag_class c;
	size_t size, n;
	char suffix[64];
	int rc = read_obj(id, &size, &n);

	if (rc < 0) {
		shell_print(s->sh, "%-6llu unreadable: %d",
			    (unsigned long long)id, rc);
		s->errors++;
		return;
	}
	diag_classify(id, g_buf, n, size, &c);

	struct hint *h = hint_find(id);

	if (h) {
		h->seen = true;
	}
	s->objects++;
	s->total += size;
	s->count[c.type][c.variant]++;
	s->bytes[c.type][c.variant] += size;
	s->suspects += c.suspect;

	/* By default list what heads a structure, and anything odd; the
	 * shape-only guesses and the unknown are counted, not listed. */
	const bool head = !c.shape && c.type != DIAG_T_UNKNOWN &&
			  c.type != DIAG_T_EMPTY;

	if (s->all || head || h || c.suspect || c.type == DIAG_T_PADB_SB) {
		if (s->printed++ == 0) {
			shell_print(s->sh, "%-6s %-8s %-19s %6s  %s", "id",
				    "type", "variant", "len", "fields");
		}
		hint_text(h, suffix, sizeof(suffix));
		diag_summary(s->sh, "", id, &c, g_buf, n, size, suffix);
	}
}

static int cmd_scan(const struct shell *sh, size_t argc, char **argv)
{
	struct blob_db_inspect_info in;
	static struct scan s;   /* the counters are too big for the stack */
	int rc = need_mount(sh, &in);

	if (rc < 0) {
		return rc;
	}
	if (argc > 2 || (argc == 2 && strcmp(argv[1], "-a") != 0)) {
		shell_error(sh, "usage: diag scan [-a]");
		return -EINVAL;
	}
	memset(&s, 0, sizeof(s));
	s.sh = sh;
	s.all = (argc == 2);
	hints_load();

	for (uint16_t bid = 0; bid < in.n_buckets; bid++) {
		for (uint32_t pass = 0;; pass++) {
			struct id_batch b = { .skip = pass * SCAN_IDS };
			struct blob_db_inspect_bucket bs;

			rc = blob_db_inspect_bucket_get(bid, &bs,
							collect_live, &b);
			if (rc == -ENODEV) {
				shell_error(sh, "unmounted during the scan");
				return rc;
			}
			if (rc < 0) {
				shell_print(sh, "bucket %u unreadable: %d", bid,
					    rc);
				s.errors++;
				break;
			}
			/* Read outside the walk: its callback must not call
			 * blob_db. */
			for (uint16_t i = 0; i < b.n; i++) {
				scan_one(&s, b.ids[i]);
			}
			if (!b.more) {
				break;
			}
		}
	}

	shell_print(sh, "");
	shell_print(sh, "%-9s %-19s %7s %10s", "type", "variant", "objects",
		    "bytes");
	for (int t = 0; t < DIAG_T_COUNT; t++) {
		const struct diag_type_info *ti = diag_type_info(t);

		for (int v = 0; v < DIAG_VARIANTS_MAX; v++) {
			if (s.count[t][v] == 0) {
				continue;
			}
			shell_print(sh, "%-9s %-19s %7u %10llu", ti->name,
				    ti->variant[v] ? ti->variant[v] : "",
				    s.count[t][v],
				    (unsigned long long)s.bytes[t][v]);
		}
	}
	shell_print(sh, "%u objects, %llu bytes, %u suspect, %u unreadable; "
		    "next_id %llu", s.objects, (unsigned long long)s.total,
		    s.suspects, s.errors, (unsigned long long)in.next_id);

	/* A registered root or a head's reference that names no object:
	 * normal for a structure created lazily, or one a crash interrupted
	 * before its first bind; a leak's opposite. */
	for (int i = 0; i < g_n_hint; i++) {
		char text[64];

		if (g_hint[i].seen) {
			continue;
		}
		hint_text(&g_hint[i], text, sizeof(text));
		shell_print(sh, "unbound: %llu%s",
			    (unsigned long long)g_hint[i].id, text);
	}
	if (g_hint_full) {
		shell_print(sh, "(more references than "
			    "CONFIG_APP_DIAG_HINTS_MAX; labels incomplete)");
	}
	return 0;
}

/* ---- diag roots ------------------------------------------------------ */

static void print_obj(const struct shell *sh, const char *prefix,
		      uint64_t id, struct diag_class *c, size_t *size,
		      size_t *n)
{
	int rc = read_obj(id, size, n);

	if (rc == -ENOENT) {
		shell_print(sh, "%s%-6llu (unbound)", prefix,
			    (unsigned long long)id);
	} else if (rc < 0) {
		shell_print(sh, "%s%-6llu unreadable: %d", prefix,
			    (unsigned long long)id, rc);
	}
	if (rc < 0) {
		c->type = DIAG_T_COUNT;
		return;
	}
	diag_classify(id, g_buf, *n, *size, c);
	diag_summary(sh, prefix, id, c, g_buf, *n, *size, "");
}

static int cmd_roots(const struct shell *sh, size_t argc, char **argv)
{
	struct blob_db_inspect_info in;
	struct diag_class c;
	size_t size, n;
	int rc = need_mount(sh, &in);

	ARG_UNUSED(argc);
	ARG_UNUSED(argv);
	if (rc < 0) {
		return rc;
	}
	print_obj(sh, "", BLOB_DB_ROOT_ID, &c, &size, &n);
	if (c.type != DIAG_T_RREG) {
		shell_print(sh, "id 1 holds no root registry");
		return 0;
	}
	hints_load();

	for (int i = 0; i < g_n_hint && g_hint[i].parent == 0; i++) {
		struct diag_ref refs[REFS_MAX];
		char key[40];

		key_text(g_hint[i].key, key, sizeof(key));
		shell_print(sh, "");
		shell_print(sh, "%s", key);
		print_obj(sh, "  ", g_hint[i].id, &c, &size, &n);
		if (c.type == DIAG_T_COUNT) {
			continue;
		}
		const int k = diag_refs(&c, g_buf, n, refs, ARRAY_SIZE(refs));

		for (int j = 0; j < k; j++) {
			char prefix[32];

			snprintk(prefix, sizeof(prefix), "    %-12s",
				 refs[j].label);
			print_obj(sh, prefix, refs[j].id, &c, &size, &n);
		}
	}
	return 0;
}

/* ---- diag show ------------------------------------------------------- */

static int cmd_show(const struct shell *sh, size_t argc, char **argv)
{
	struct blob_db_inspect_info in;
	struct diag_class c;
	enum diag_type t;
	uint64_t id;
	size_t size, n;
	int rc = need_mount(sh, &in);

	if (rc < 0) {
		return rc;
	}
	if (parse_u64(sh, argv[1], &id) < 0) {
		return -EINVAL;
	}
	if (argc > 2 && diag_type_by_name(argv[2], &t) < 0) {
		shell_error(sh, "unknown type %s; see `diag formats`", argv[2]);
		return -EINVAL;
	}
	rc = read_obj(id, &size, &n);
	if (rc == -ENOENT) {
		shell_error(sh, "%llu: not bound", (unsigned long long)id);
		return rc;
	}
	if (rc < 0) {
		shell_error(sh, "%llu: read: %d", (unsigned long long)id, rc);
		return rc;
	}
	if (argc > 2) {
		rc = diag_force(id, t, g_buf, n, size, &c);
		if (rc < 0) {
			shell_error(sh, "%llu: %zu bytes, too short for %s",
				    (unsigned long long)id, size, argv[2]);
			return rc;
		}
	} else {
		diag_classify(id, g_buf, n, size, &c);
	}
	diag_decode(sh, id, &c, g_buf, n, size);

	/* A reference to nothing: a logring's reserved next id at the tail,
	 * a structure created lazily, or damage. */
	struct diag_ref refs[REFS_MAX];
	const int k = diag_refs(&c, g_buf, n, refs, ARRAY_SIZE(refs));

	for (int i = 0; i < k; i++) {
		if (!blob_db_exists(refs[i].id)) {
			shell_print(sh, "  %s %llu is not bound", refs[i].label,
				    (unsigned long long)refs[i].id);
		}
	}
	return 0;
}

/* ---- diag formats ---------------------------------------------------- */

static int cmd_formats(const struct shell *sh, size_t argc, char **argv)
{
	ARG_UNUSED(argc);
	ARG_UNUSED(argv);
	for (int t = 0; t < DIAG_T_COUNT; t++) {
		const struct diag_type_info *ti = diag_type_info(t);

		shell_print(sh, "%-9s %s", ti->name, ti->what);
		for (int v = 0; v < DIAG_VARIANTS_MAX && ti->variant[v] &&
		     ti->variant[v][0]; v++) {
			shell_print(sh, "%-9s   %s", "", ti->variant[v]);
		}
	}
	shell_print(sh, "Types without a magic (kvbucket, logentry, cbor, and "
		    "persondb) are guessed from their layout: [shape].");
	return 0;
}

SHELL_STATIC_SUBCMD_SET_CREATE(sub_diag,
	SHELL_CMD_ARG(scan, NULL,
		      "[-a] classify every live object; -a lists all, not "
		      "only structure heads",
		      cmd_scan, 1, 1),
	SHELL_CMD_ARG(roots, NULL,
		      "the root registry, each root and what it points at",
		      cmd_roots, 1, 0),
	SHELL_CMD_ARG(show, NULL,
		      "<id> [type] decode one object, as recognised or as "
		      "<type>",
		      cmd_show, 2, 1),
	SHELL_CMD_ARG(formats, NULL,
		      "the structure formats and past variants this build "
		      "knows",
		      cmd_formats, 1, 0),
	SHELL_SUBCMD_SET_END
);

SHELL_CMD_REGISTER(diag, &sub_diag,
		   "recognise and decode the structures in the store", NULL);
```
